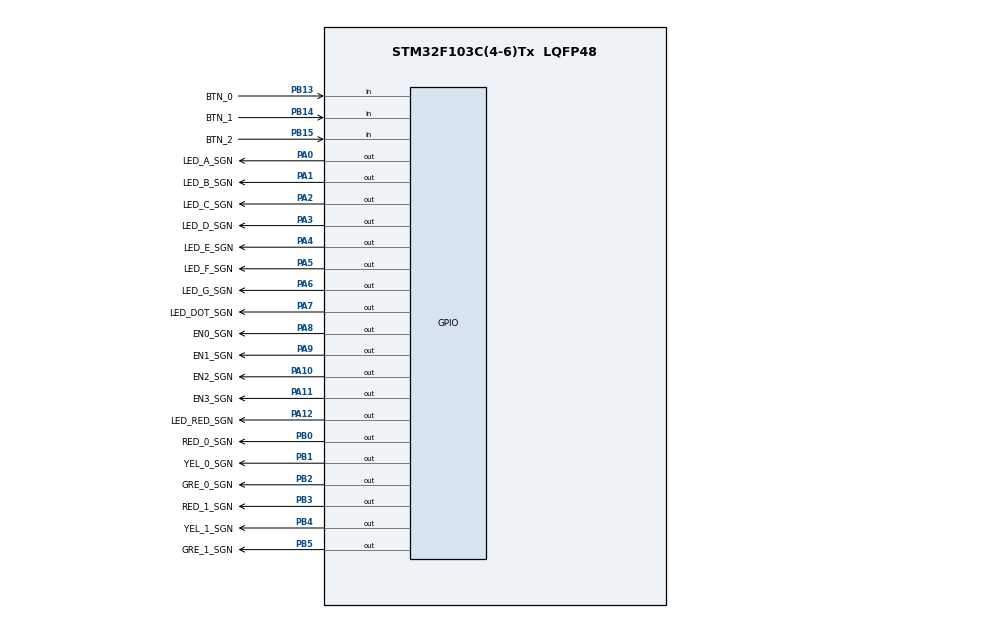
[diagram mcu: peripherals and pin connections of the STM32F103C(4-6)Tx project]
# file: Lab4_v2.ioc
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Mcu.Family=STM32F1
Mcu.Name=STM32F103C(4-6)Tx
Mcu.Package=LQFP48
NVIC.PriorityGroup=NVIC_PRIORITYGROUP_4
NVIC.TIM2_IRQn=true\:0\:0\:false\:false\:true\:true\:true\:true
PA0-WKUP.GPIO_Label=LED_A_SGN
PA0-WKUP.Signal=GPIO_Output
PA1.GPIO_Label=LED_B_SGN
PA1.Signal=GPIO_Output
PA10.GPIO_Label=EN2_SGN
PA10.Signal=GPIO_Output
PA11.GPIO_Label=EN3_SGN
PA11.Signal=GPIO_Output
PA12.GPIO_Label=LED_RED_SGN
PA12.Signal=GPIO_Output
PA13.Mode=Serial_Wire
PA13.Signal=SYS_JTMS-SWDIO
PA14.Mode=Serial_Wire
PA14.Signal=SYS_JTCK-SWCLK
PA2.GPIO_Label=LED_C_SGN
PA2.Signal=GPIO_Output
PA3.GPIO_Label=LED_D_SGN
PA3.Signal=GPIO_Output
PA4.GPIO_Label=LED_E_SGN
PA4.Signal=GPIO_Output
PA5.GPIO_Label=LED_F_SGN
PA5.Signal=GPIO_Output
PA6.GPIO_Label=LED_G_SGN
PA6.Signal=GPIO_Output
PA7.GPIO_Label=LED_DOT_SGN
PA7.Signal=GPIO_Output
PA8.GPIO_Label=EN0_SGN
PA8.Signal=GPIO_Output
PA9.GPIO_Label=EN1_SGN
PA9.Signal=GPIO_Output
PB0.GPIO_Label=RED_0_SGN
PB0.Signal=GPIO_Output
PB1.GPIO_Label=YEL_0_SGN
PB1.Signal=GPIO_Output
PB13.GPIO_Label=BTN_0
PB13.GPIO_PuPd=GPIO_PULLUP
PB13.Signal=GPIO_Input
PB14.GPIO_Label=BTN_1
PB14.GPIO_PuPd=GPIO_PULLUP
PB14.Signal=GPIO_Input
PB15.GPIO_Label=BTN_2
PB15.GPIO_PuPd=GPIO_PULLUP
PB15.Signal=GPIO_Input
PB2.GPIO_Label=GRE_0_SGN
PB2.Signal=GPIO_Output
PB3.GPIO_Label=RED_1_SGN
PB3.Signal=GPIO_Output
PB4.GPIO_Label=YEL_1_SGN
PB4.Signal=GPIO_Output
PB5.GPIO_Label=GRE_1_SGN
PB5.Signal=GPIO_Output
ProjectManager.HeapSize=0x200
ProjectManager.StackSize=0x400
ProjectManager.TargetToolchain=STM32CubeIDE
RCC.APB1Freq_Value=8000000
RCC.APB2Freq_Value=8000000
TIM2.Period=9
TIM2.Prescaler=7999
VP_TIM2_VS_ClockSourceINT.Mode=Internal
board=custom

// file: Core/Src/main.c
/* USER CODE BEGIN Header */
/**
  ******************************************************************************
  * @file           : main.c
  * @brief          : Main program body
  ******************************************************************************
  * @attention
  *
  * Copyright (c) 2025 STMicroelectronics.
  * All rights reserved.
  *
  * This software is licensed under terms that can be found in the LICENSE file
  * in the root directory of this software component.
  * If no LICENSE file comes with this software, it is provided AS-IS.
  *
  ******************************************************************************
  */
/* USER CODE END Header */
#include "main.h"
#include "Scheduler.h"
#include "Task.h"

TIM_HandleTypeDef htim2;

void SystemClock_Config(void);
static void MX_GPIO_Init(void);
static void MX_TIM2_Init(void);

int main(void)
{

  /* MCU Configuration--------------------------------------------------------*/

  /* Reset of all peripherals, Initializes the Flash interface and the Systick. */
  HAL_Init();

  /* Configure the system clock */
  SystemClock_Config();

  /* Initialize all configured peripherals */
  MX_GPIO_Init();
  MX_TIM2_Init();
  HAL_TIM_Base_Start_IT(&htim2);

  /* Infinite loop */
  /* USER CODE BEGIN WHILE */
  SCH_init();
  SCH_Add_Task(Task1, 50, 250);
  SCH_Add_Task(Task2, 100, 250);
  SCH_Add_Task(Task3, 150, 250);
  SCH_Add_Task(Task4, 200, 250);
  SCH_Add_Task(Task5, 250, 250);
  while (1)
  {
    /* USER CODE END WHILE */
	  SCH_Dispatch_Tasks();
  }
}

void SystemClock_Config(void)
{
  RCC_OscInitTypeDef RCC_OscInitStruct = {0};
  RCC_ClkInitTypeDef RCC_ClkInitStruct = {0};

  /** Initializes the RCC Oscillators according to the specified parameters
  * in the RCC_OscInitTypeDef structure.
  */
  RCC_OscInitStruct.OscillatorType = RCC_OSCILLATORTYPE_HSI;
  RCC_OscInitStruct.HSIState = RCC_HSI_ON;
  RCC_OscInitStruct.HSICalibrationValue = RCC_HSICALIBRATION_DEFAULT;
  RCC_OscInitStruct.PLL.PLLState = RCC_PLL_NONE;
  if (HAL_RCC_OscConfig(&RCC_OscInitStruct) != HAL_OK)
  {
    Error_Handler();
  }

  /** Initializes the CPU, AHB and APB buses clocks
  */
  RCC_ClkInitStruct.ClockType = RCC_CLOCKTYPE_HCLK|RCC_CLOCKTYPE_SYSCLK
                              |RCC_CLOCKTYPE_PCLK1|RCC_CLOCKTYPE_PCLK2;
  RCC_ClkInitStruct.SYSCLKSource = RCC_SYSCLKSOURCE_HSI;
  RCC_ClkInitStruct.AHBCLKDivider = RCC_SYSCLK_DIV1;
  RCC_ClkInitStruct.APB1CLKDivider = RCC_HCLK_DIV1;
  RCC_ClkInitStruct.APB2CLKDivider = RCC_HCLK_DIV1;

  if (HAL_RCC_ClockConfig(&RCC_ClkInitStruct, FLASH_LATENCY_0) != HAL_OK)
  {
    Error_Handler();
  }
}

static void MX_TIM2_Init(void)
{

  TIM_ClockConfigTypeDef sClockSourceConfig = {0};
  TIM_MasterConfigTypeDef sMasterConfig = {0};

  htim2.Instance = TIM2;
  htim2.Init.Prescaler = 7999;
  htim2.Init.CounterMode = TIM_COUNTERMODE_UP;
  htim2.Init.Period = 9;
  htim2.Init.ClockDivision = TIM_CLOCKDIVISION_DIV1;
  htim2.Init.AutoReloadPreload = TIM_AUTORELOAD_PRELOAD_DISABLE;
  if (HAL_TIM_Base_Init(&htim2) != HAL_OK)
  {
    Error_Handler();
  }
  sClockSourceConfig.ClockSource = TIM_CLOCKSOURCE_INTERNAL;
  if (HAL_TIM_ConfigClockSource(&htim2, &sClockSourceConfig) != HAL_OK)
  {
    Error_Handler();
  }
  sMasterConfig.MasterOutputTrigger = TIM_TRGO_RESET;
  sMasterConfig.MasterSlaveMode = TIM_MASTERSLAVEMODE_DISABLE;
  if (HAL_TIMEx_MasterConfigSynchronization(&htim2, &sMasterConfig) != HAL_OK)
  {
    Error_Handler();
  }

}

static void MX_GPIO_Init(void)
{
  GPIO_InitTypeDef GPIO_InitStruct = {0};

  /* GPIO Ports Clock Enable */
  __HAL_RCC_GPIOA_CLK_ENABLE();
  __HAL_RCC_GPIOB_CLK_ENABLE();

  /*Configure GPIO pin Output Level */
  HAL_GPIO_WritePin(GPIOA, LED_A_SGN_Pin|LED_B_SGN_Pin|LED_C_SGN_Pin|LED_D_SGN_Pin
                          |LED_E_SGN_Pin|LED_F_SGN_Pin|LED_G_SGN_Pin|LED_DOT_SGN_Pin
                          |EN0_SGN_Pin|EN1_SGN_Pin|EN2_SGN_Pin|EN3_SGN_Pin
                          |LED_RED_SGN_Pin, GPIO_PIN_RESET);

  /*Configure GPIO pin Output Level */
  HAL_GPIO_WritePin(GPIOB, RED_0_SGN_Pin|YEL_0_SGN_Pin|GRE_0_SGN_Pin|RED_1_SGN_Pin
                          |YEL_1_SGN_Pin|GRE_1_SGN_Pin, GPIO_PIN_RESET);

  /*Configure GPIO pins : LED_A_SGN_Pin LED_B_SGN_Pin LED_C_SGN_Pin LED_D_SGN_Pin
                           LED_E_SGN_Pin LED_F_SGN_Pin LED_G_SGN_Pin LED_DOT_SGN_Pin
                           EN0_SGN_Pin EN1_SGN_Pin EN2_SGN_Pin EN3_SGN_Pin
                           LED_RED_SGN_Pin */
  GPIO_InitStruct.Pin = LED_A_SGN_Pin|LED_B_SGN_Pin|LED_C_SGN_Pin|LED_D_SGN_Pin
                          |LED_E_SGN_Pin|LED_F_SGN_Pin|LED_G_SGN_Pin|LED_DOT_SGN_Pin
                          |EN0_SGN_Pin|EN1_SGN_Pin|EN2_SGN_Pin|EN3_SGN_Pin
                          |LED_RED_SGN_Pin;
  GPIO_InitStruct.Mode = GPIO_MODE_OUTPUT_PP;
  GPIO_InitStruct.Pull = GPIO_NOPULL;
  GPIO_InitStruct.Speed = GPIO_SPEED_FREQ_LOW;
  HAL_GPIO_Init(GPIOA, &GPIO_InitStruct);

  /*Configure GPIO pins : RED_0_SGN_Pin YEL_0_SGN_Pin GRE_0_SGN_Pin RED_1_SGN_Pin
                           YEL_1_SGN_Pin GRE_1_SGN_Pin */
  GPIO_InitStruct.Pin = RED_0_SGN_Pin|YEL_0_SGN_Pin|GRE_0_SGN_Pin|RED_1_SGN_Pin
                          |YEL_1_SGN_Pin|GRE_1_SGN_Pin;
  GPIO_InitStruct.Mode = GPIO_MODE_OUTPUT_PP;
  GPIO_InitStruct.Pull = GPIO_NOPULL;
  GPIO_InitStruct.Speed = GPIO_SPEED_FREQ_LOW;
  HAL_GPIO_Init(GPIOB, &GPIO_InitStruct);

  /*Configure GPIO pins : BTN_0_Pin BTN_1_Pin BTN_2_Pin */
  GPIO_InitStruct.Pin = BTN_0_Pin|BTN_1_Pin|BTN_2_Pin;
  GPIO_InitStruct.Mode = GPIO_MODE_INPUT;
  GPIO_InitStruct.Pull = GPIO_PULLUP;
  HAL_GPIO_Init(GPIOB, &GPIO_InitStruct);

}

/* USER CODE BEGIN 4 */
void HAL_TIM_PeriodElapsedCallback(TIM_HandleTypeDef *htim){
	SCH_Update();
}
/* USER CODE END 4 */

void Error_Handler(void)
{
  __disable_irq();
  while (1)
  {
  }
}
